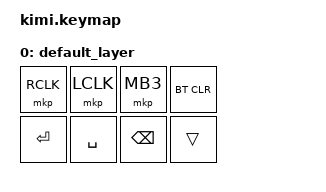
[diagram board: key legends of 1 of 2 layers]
#include <behaviors.dtsi>
#include <dt-bindings/zmk/bt.h>
#include <dt-bindings/zmk/keys.h>
#include <dt-bindings/zmk/mouse.h>
#include <dt-bindings/zmk/pointing.h>

&trackball {
    automouse-layer = <2>;
    scroll-layers = <1>;

    // arrows {
    //     layers = <3>;
    //     bindings =
    //         <&kp RIGHT_ARROW>,
    //         <&kp LEFT_ARROW>,
    //         <&kp UP_ARROW>,
    //         <&kp DOWN_ARROW>;

    //     tick = <10>;
    //     wait-ms = <5>;
    //     tap-ms = <5>;
    // };
};

/ {
    behaviors {
        // カーソルの検出

        mouse_mv: mouse_cursor_move {
            compatible = "zmk,behavior-sensor-rotate-var";
            #sensor-binding-cells = <2>;
            bindings = <&mmv>, <&mmv>;
            tap-ms = <10>;
        };

        // ホイールの検出

        mouse_scrl: mouse_wheel_scrl {
            compatible = "zmk,behavior-sensor-rotate-var";
            #sensor-binding-cells = <2>;
            bindings = <&msc>, <&msc>;
            tap-ms = <10>;
        };

        };
    };

/ {
    keymap {
        compatible = "zmk,keymap";

        default_layer {
            bindings = <
                // row0（上段）右から左に書く
                &mkp RCLK       &mkp LCLK       &mkp MB3   &bt BT_CLR

                // row1（下段）右から左に書く
                &kp ENTER       &kp SPACE       &kp BACKSPACE  &trans
            >;
	};

//    auto_mouse_layer {
//            bindings = <
//                &mkp RCLK &mkp LCLK &mkp MB3
//        >;
//    };

    scroll_layer {
            bindings = <
                &trans  &trans  &trans
        >;
    };
    
    };

    combos {
        compatible = "zmk,combos";

        // Key1 + 2 =

        combo_layer1 {
            bindings = <&mo 1>;
            key-positions = <1 2>;
            timeout-ms = <50>;
        };
    };
};
